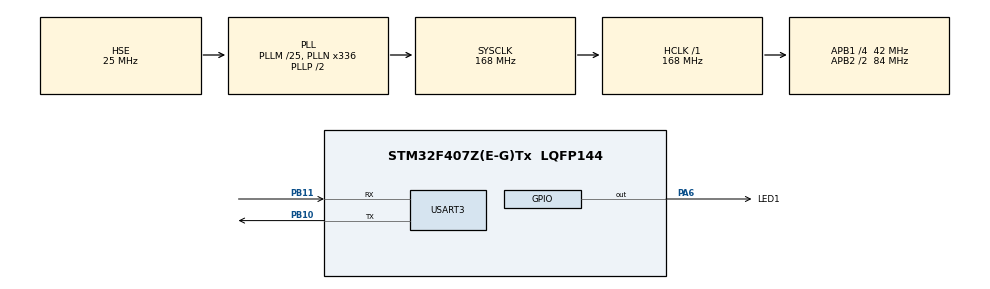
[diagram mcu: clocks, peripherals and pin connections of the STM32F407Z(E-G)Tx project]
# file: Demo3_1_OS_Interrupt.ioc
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FREERTOS.Tasks01=Task_LED1,24,256,AppTask_LED1,Default,NULL,Dynamic,NULL,NULL
FREERTOS.configUSE_NEWLIB_REENTRANT=1
Mcu.Family=STM32F4
Mcu.Name=STM32F407Z(E-G)Tx
Mcu.Package=LQFP144
NVIC.PriorityGroup=NVIC_PRIORITYGROUP_4
NVIC.RTC_WKUP_IRQn=true\:7\:0\:true\:false\:true\:false\:true\:true\:true
NVIC.TIM6_DAC_IRQn=true\:0\:0\:true\:false\:true\:false\:false\:true\:true
NVIC.TimeBase=TIM6_DAC_IRQn
NVIC.TimeBaseIP=TIM6
PA13.Mode=Serial_Wire
PA13.Signal=SYS_JTMS-SWDIO
PA14.Mode=Serial_Wire
PA14.Signal=SYS_JTCK-SWCLK
PA6.GPIO_Label=LED1
PA6.GPIO_Speed=GPIO_SPEED_FREQ_HIGH
PA6.PinState=GPIO_PIN_SET
PA6.Signal=GPIO_Output
PB10.Mode=Asynchronous
PB10.Signal=USART3_TX
PB11.Mode=Asynchronous
PB11.Signal=USART3_RX
PC14-OSC32_IN.Mode=LSE-External-Oscillator
PC14-OSC32_IN.Signal=RCC_OSC32_IN
PC15-OSC32_OUT.Mode=LSE-External-Oscillator
PC15-OSC32_OUT.Signal=RCC_OSC32_OUT
PH0-OSC_IN.Mode=HSE-External-Oscillator
PH0-OSC_IN.Signal=RCC_OSC_IN
PH1-OSC_OUT.Mode=HSE-External-Oscillator
PH1-OSC_OUT.Signal=RCC_OSC_OUT
ProjectManager.HeapSize=0x200
ProjectManager.StackSize=0x400
ProjectManager.TargetToolchain=STM32CubeIDE
RCC.48MHZClocksFreq_Value=84000000
RCC.AHBFreq_Value=168000000
RCC.APB1CLKDivider=RCC_HCLK_DIV4
RCC.APB1Freq_Value=42000000
RCC.APB1TimFreq_Value=84000000
RCC.APB2CLKDivider=RCC_HCLK_DIV2
RCC.APB2Freq_Value=84000000
RCC.APB2TimFreq_Value=168000000
RCC.CortexFreq_Value=168000000
RCC.HCLKFreq_Value=168000000
RCC.HSE_VALUE=25000000
RCC.HSI_VALUE=16000000
RCC.PLLM=25
RCC.PLLN=336
RCC.PLLSourceVirtual=RCC_PLLSOURCE_HSE
RCC.RCC_RTC_Clock_Source=RCC_RTCCLKSOURCE_LSE
RCC.RCC_RTC_Clock_SourceVirtual=RCC_RTCCLKSOURCE_LSE
RCC.SYSCLKFreq_VALUE=168000000
RCC.SYSCLKSource=RCC_SYSCLKSOURCE_PLLCLK
RCC.VCOOutputFreq_Value=336000000
RTC.Date=19
RTC.Format=RTC_FORMAT_BIN
RTC.Hours=12
RTC.Minutes=45
RTC.Month=RTC_MONTH_APRIL
RTC.Seconds=30
RTC.WakeUpClock=RTC_WAKEUPCLOCK_CK_SPRE_16BITS
RTC.WakeUpCounter=0
RTC.WeekDay=RTC_WEEKDAY_FRIDAY
RTC.Year=25
USART3.VirtualMode=VM_ASYNC
VP_FREERTOS_VS_CMSIS_V2.Mode=CMSIS_V2
VP_RTC_VS_RTC_Activate.Mode=RTC_Enabled
VP_RTC_VS_RTC_Calendar.Mode=RTC_Calendar
VP_RTC_VS_RTC_WakeUp_intern.Mode=WakeUp
VP_SYS_VS_tim6.Mode=TIM6
board=custom

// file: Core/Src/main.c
/* USER CODE BEGIN Header */
/**
  ******************************************************************************
  * @file           : main.c
  * @brief          : Main program body
  ******************************************************************************
  * @attention
  *
  * Copyright (c) 2025 STMicroelectronics.
  * All rights reserved.
  *
  * This software is licensed under terms that can be found in the LICENSE file
  * in the root directory of this software component.
  * If no LICENSE file comes with this software, it is provided AS-IS.
  *
  ******************************************************************************
  */
/* USER CODE END Header */
#include "main.h"
#include "cmsis_os.h"
#include "rtc.h"
#include "usart.h"
#include "gpio.h"

void SystemClock_Config(void);
void MX_FREERTOS_Init(void);

int main(void)
{

  /* MCU Configuration--------------------------------------------------------*/

  /* Reset of all peripherals, Initializes the Flash interface and the Systick. */
  HAL_Init();

  /* Configure the system clock */
  SystemClock_Config();

  /* Initialize all configured peripherals */
  MX_GPIO_Init();
  MX_RTC_Init();
  MX_USART3_UART_Init();
  /* USER CODE BEGIN 2 */
  uint8_t startstr[] = "Demo3-1_RTOS_Interrupt: First, RTC priority=1.\r\n\r\n";
  HAL_UART_Transmit(&huart3,startstr,sizeof(startstr),0xFFFF);

  //Tests for different combinations of ISR and Task.
  uint8_t startstr1[] = "HAL_Delay(1000) in RTC ISR.\r\n";
  HAL_UART_Transmit(&huart3,startstr1,sizeof(startstr1),0xFFFF);

  uint8_t startstr2[] = "RTC priority=7.\r\n";
  HAL_UART_Transmit(&huart3,startstr2,sizeof(startstr2),0xFFFF);

  uint8_t startstr3[] = "Disable interrupt in task.\r\n";
  HAL_UART_Transmit(&huart3,startstr3,sizeof(startstr3),0xFFFF);

  uint8_t startstr4[] = "vTaskDelay(2000) in task.\r\n\r\n";
  HAL_UART_Transmit(&huart3,startstr4,sizeof(startstr4),0xFFFF);

  /* USER CODE END 2 */

  /* Init scheduler */
  osKernelInitialize();

  /* Call init function for freertos objects (in cmsis_os2.c) */
  MX_FREERTOS_Init();

  /* Start scheduler */
  osKernelStart();

  /* We should never get here as control is now taken by the scheduler */

  /* Infinite loop */
  while (1)
  {

  }
}

void SystemClock_Config(void)
{
  RCC_OscInitTypeDef RCC_OscInitStruct = {0};
  RCC_ClkInitTypeDef RCC_ClkInitStruct = {0};

  /** Configure the main internal regulator output voltage
  */
  __HAL_RCC_PWR_CLK_ENABLE();
  __HAL_PWR_VOLTAGESCALING_CONFIG(PWR_REGULATOR_VOLTAGE_SCALE1);

  /** Initializes the RCC Oscillators according to the specified parameters
  * in the RCC_OscInitTypeDef structure.
  */
  RCC_OscInitStruct.OscillatorType = RCC_OSCILLATORTYPE_HSE|RCC_OSCILLATORTYPE_LSE;
  RCC_OscInitStruct.HSEState = RCC_HSE_ON;
  RCC_OscInitStruct.LSEState = RCC_LSE_ON;
  RCC_OscInitStruct.PLL.PLLState = RCC_PLL_ON;
  RCC_OscInitStruct.PLL.PLLSource = RCC_PLLSOURCE_HSE;
  RCC_OscInitStruct.PLL.PLLM = 25;
  RCC_OscInitStruct.PLL.PLLN = 336;
  RCC_OscInitStruct.PLL.PLLP = RCC_PLLP_DIV2;
  RCC_OscInitStruct.PLL.PLLQ = 4;
  if (HAL_RCC_OscConfig(&RCC_OscInitStruct) != HAL_OK)
  {
    Error_Handler();
  }

  /** Initializes the CPU, AHB and APB buses clocks
  */
  RCC_ClkInitStruct.ClockType = RCC_CLOCKTYPE_HCLK|RCC_CLOCKTYPE_SYSCLK
                              |RCC_CLOCKTYPE_PCLK1|RCC_CLOCKTYPE_PCLK2;
  RCC_ClkInitStruct.SYSCLKSource = RCC_SYSCLKSOURCE_PLLCLK;
  RCC_ClkInitStruct.AHBCLKDivider = RCC_SYSCLK_DIV1;
  RCC_ClkInitStruct.APB1CLKDivider = RCC_HCLK_DIV4;
  RCC_ClkInitStruct.APB2CLKDivider = RCC_HCLK_DIV2;

  if (HAL_RCC_ClockConfig(&RCC_ClkInitStruct, FLASH_LATENCY_5) != HAL_OK)
  {
    Error_Handler();
  }
}

void HAL_TIM_PeriodElapsedCallback(TIM_HandleTypeDef *htim)
{
  if (htim->Instance == TIM6)
  {
    HAL_IncTick();
  }
}

void Error_Handler(void)
{
  __disable_irq();
  while (1)
  {
  }
}

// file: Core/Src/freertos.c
/* USER CODE BEGIN Header */
/**
  ******************************************************************************
  * File Name          : freertos.c
  * Description        : Code for freertos applications
  ******************************************************************************
  * @attention
  *
  * Copyright (c) 2025 STMicroelectronics.
  * All rights reserved.
  *
  * This software is licensed under terms that can be found in the LICENSE file
  * in the root directory of this software component.
  * If no LICENSE file comes with this software, it is provided AS-IS.
  *
  ******************************************************************************
  */
/* USER CODE END Header */

#include "FreeRTOS.h"
#include "task.h"
#include "main.h"
#include "cmsis_os.h"

/* Definitions for Task_LED1 */
osThreadId_t Task_LED1Handle;
const osThreadAttr_t Task_LED1_attributes = {
  .name = "Task_LED1",
  .stack_size = 256 * 4,
  .priority = (osPriority_t) osPriorityNormal,
};

void AppTask_LED1(void *argument);

void MX_FREERTOS_Init(void); /* (MISRA C 2004 rule 8.1) */

void MX_FREERTOS_Init(void) {

  /* Create the thread(s) */
  /* creation of Task_LED1 */
  Task_LED1Handle = osThreadNew(AppTask_LED1, NULL, &Task_LED1_attributes);

}

void AppTask_LED1(void *argument)
{
  /* USER CODE BEGIN AppTask_LED1 */
  /* Infinite loop */
  for(;;)
  {
	  taskDISABLE_INTERRUPTS();
	  //taskENTER_CRITICAL();
	  HAL_GPIO_TogglePin(GPIOA, GPIO_PIN_6);		///<PA6=LED1 flashing
	  vTaskDelay(pdMS_TO_TICKS(2000));					///<The delay is 2000ms, but the task also enters a blocking state, which will inevitably lead to the interruption of PendSV for task scheduling.
	  //HAL_Delay(2000);											///<Run continuously for 2000ms, the task is in operation
	  //taskEXIT_CRITICAL();
	  taskENABLE_INTERRUPTS();
  }
  /* USER CODE END AppTask_LED1 */
}
